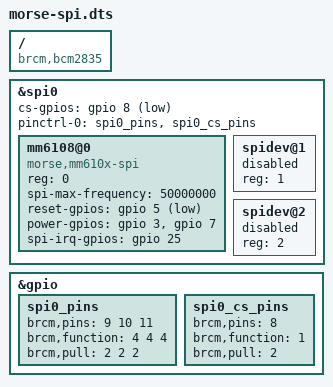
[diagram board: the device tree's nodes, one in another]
/dts-v1/;
/plugin/;

/ {
    compatible = "brcm,bcm2835", "brcm,bcm2711", "brcm,bcm2709", "brcm,bcm2708";

    fragment@0 {
        target = <&spi0>;
        __overlay__ {
            status = "okay";
            #address-cells = <1>;
            #size-cells   = <0>;

            cs-gpios = <&gpio 8 1>;

            pinctrl-names = "default";
            pinctrl-0 = <&spi0_pins &spi0_cs_pins>;

            mm6108@0 {
                compatible = "morse,mm610x-spi";
                reg = <0>;  
                spi-max-frequency = <50000000>;

                reset-gpios    = <&gpio 5  1>;
                power-gpios    = <&gpio 3  0>, <&gpio 7 0>;
                spi-irq-gpios  = <&gpio 25 0>;

                status = "okay";
            };

            spidev@1 { reg = <1>; status = "disabled"; };
            spidev@2 { reg = <2>; status = "disabled"; };
        };
    };

    fragment@1 {
        target = <&gpio>;
        __overlay__ {
            spi0_pins: spi0_pins {
                brcm,pins     = <9 10 11>;
                brcm,function = <4  4  4>;
                brcm,pull     = <2  2  2>; 
            };

            spi0_cs_pins: spi0_cs_pins {
                brcm,pins     = <8>;
                brcm,function = <1>;
                brcm,pull     = <2>;
            };
        };
    };
};
